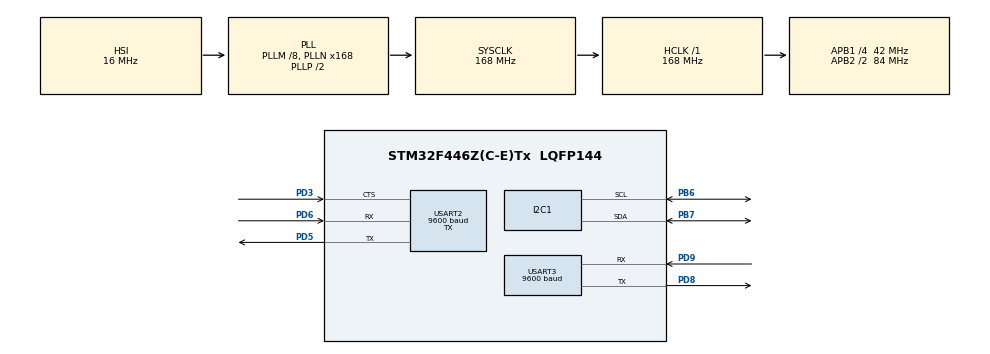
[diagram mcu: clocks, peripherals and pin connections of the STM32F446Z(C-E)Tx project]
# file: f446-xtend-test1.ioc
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Mcu.Family=STM32F4
Mcu.Name=STM32F446Z(C-E)Tx
Mcu.Package=LQFP144
NVIC.PriorityGroup=NVIC_PRIORITYGROUP_4
NVIC.TIM8_TRG_COM_TIM14_IRQn=true\:15\:0\:false\:false\:true\:false\:true
NVIC.TimeBase=TIM8_TRG_COM_TIM14_IRQn
NVIC.TimeBaseIP=TIM14
PB6.Mode=I2C
PB6.Signal=I2C1_SCL
PB7.Mode=I2C
PB7.Signal=I2C1_SDA
PC10.Signal=UART4_TX
PC11.Signal=UART4_RX
PD3.Mode=CTS_Only
PD3.Signal=USART2_CTS
PD5.Mode=Asynchronous
PD5.Signal=USART2_TX
PD6.Mode=Asynchronous
PD6.Signal=USART2_RX
PD8.Mode=Asynchronous
PD8.Signal=USART3_TX
PD9.Mode=Asynchronous
PD9.Signal=USART3_RX
ProjectManager.HeapSize=0x200
ProjectManager.StackSize=0x400
ProjectManager.TargetToolchain=STM32CubeIDE
RCC.48MHZClocksFreq_Value=24000000
RCC.AHBFreq_Value=168000000
RCC.APB1CLKDivider=RCC_HCLK_DIV4
RCC.APB1Freq_Value=42000000
RCC.APB1TimFreq_Value=84000000
RCC.APB2CLKDivider=RCC_HCLK_DIV2
RCC.APB2Freq_Value=84000000
RCC.APB2TimFreq_Value=168000000
RCC.CortexFreq_Value=168000000
RCC.HCLKFreq_Value=168000000
RCC.HSE_VALUE=8000000
RCC.HSI_VALUE=16000000
RCC.PLLM=8
RCC.PLLMUL=RCC_PLL_MUL9
RCC.PLLN=168
RCC.PLLQ=7
RCC.PRESCALERUSB=RCC_USBCLKSOURCE_PLL_DIV1_5
RCC.SYSCLKFreq_VALUE=168000000
RCC.SYSCLKSource=RCC_SYSCLKSOURCE_PLLCLK
RCC.SYSCLKSourceVirtual=RCC_SYSCLKSOURCE_PLLCLK
RCC.USBFreq_Value=48000000
RCC.VCOOutputFreq_Value=336000000
USART2.BaudRate=9600
USART2.Mode=MODE_TX
USART2.OverSampling=UART_OVERSAMPLING_8
USART2.VirtualMode=VM_ASYNC
USART3.BaudRate=9600
USART3.VirtualMode=VM_ASYNC
VP_SYS_VS_tim14.Mode=TIM14
board=NUCLEO-F446ZE

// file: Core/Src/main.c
/* USER CODE BEGIN Header */
/**
  ******************************************************************************
  * @file           : main.c
  * @brief          : Main program body
  ******************************************************************************
  * @attention
  *
  * <h2><center>&copy; Copyright (c) 2022 STMicroelectronics.
  * All rights reserved.</center></h2>
  *
  * This software component is licensed by ST under BSD 3-Clause license,
  * the "License"; You may not use this file except in compliance with the
  * License. You may obtain a copy of the License at:
  *                        opensource.org/licenses/BSD-3-Clause
  *
  ******************************************************************************
  */
/* USER CODE END Header */
#include "main.h"

/* USER CODE BEGIN Includes */
#include "stdio.h"
/* USER CODE END Includes */

I2C_HandleTypeDef hi2c1;

UART_HandleTypeDef huart2;
UART_HandleTypeDef huart3;

void SystemClock_Config(void);
static void MX_GPIO_Init(void);
static void MX_USART3_UART_Init(void);
static void MX_I2C1_Init(void);
static void MX_USART2_UART_Init(void);

/* USER CODE BEGIN PFP */
static void XTend_Transmit(char *Msg);
/* USER CODE END PFP */

int main(void)
{

  /* MCU Configuration--------------------------------------------------------*/

  /* Reset of all peripherals, Initializes the Flash interface and the Systick. */
  HAL_Init();

  /* Configure the system clock */
  SystemClock_Config();

  /* Initialize all configured peripherals */
  MX_GPIO_Init();
  MX_USART3_UART_Init(); // Serial monitor
  MX_I2C1_Init();
  MX_USART2_UART_Init(); // XTend DIn, DOut, !CTS
  /* USER CODE BEGIN 2 */

  uint8_t Start[] = "Starting XTend\r\n";
  HAL_UART_Transmit(&huart3, Start, 16, HAL_MAX_DELAY);

  XTend_Transmit("You would not believe your eyes\r\n");

  /* USER CODE END 2 */

  /* Infinite loop */
  /* USER CODE BEGIN WHILE */
  while (1)
  {

	  uint8_t Msg[] = "If ten thousand fireflies\r\n";
	  HAL_UART_Transmit(&huart2, Msg, 27, HAL_Delay);

	  HAL_Delay(30000);
    /* USER CODE END WHILE */

  }
}

void SystemClock_Config(void)
{
  RCC_OscInitTypeDef RCC_OscInitStruct = {0};
  RCC_ClkInitTypeDef RCC_ClkInitStruct = {0};

  /** Configure the main internal regulator output voltage
  */
  __HAL_RCC_PWR_CLK_ENABLE();
  __HAL_PWR_VOLTAGESCALING_CONFIG(PWR_REGULATOR_VOLTAGE_SCALE1);
  /** Initializes the RCC Oscillators according to the specified parameters
  * in the RCC_OscInitTypeDef structure.
  */
  RCC_OscInitStruct.OscillatorType = RCC_OSCILLATORTYPE_HSI;
  RCC_OscInitStruct.HSIState = RCC_HSI_ON;
  RCC_OscInitStruct.HSICalibrationValue = RCC_HSICALIBRATION_DEFAULT;
  RCC_OscInitStruct.PLL.PLLState = RCC_PLL_ON;
  RCC_OscInitStruct.PLL.PLLSource = RCC_PLLSOURCE_HSI;
  RCC_OscInitStruct.PLL.PLLM = 8;
  RCC_OscInitStruct.PLL.PLLN = 168;
  RCC_OscInitStruct.PLL.PLLP = RCC_PLLP_DIV2;
  RCC_OscInitStruct.PLL.PLLQ = 7;
  RCC_OscInitStruct.PLL.PLLR = 2;
  if (HAL_RCC_OscConfig(&RCC_OscInitStruct) != HAL_OK)
  {
    Error_Handler();
  }
  /** Initializes the CPU, AHB and APB buses clocks
  */
  RCC_ClkInitStruct.ClockType = RCC_CLOCKTYPE_HCLK|RCC_CLOCKTYPE_SYSCLK
                              |RCC_CLOCKTYPE_PCLK1|RCC_CLOCKTYPE_PCLK2;
  RCC_ClkInitStruct.SYSCLKSource = RCC_SYSCLKSOURCE_PLLCLK;
  RCC_ClkInitStruct.AHBCLKDivider = RCC_SYSCLK_DIV1;
  RCC_ClkInitStruct.APB1CLKDivider = RCC_HCLK_DIV4;
  RCC_ClkInitStruct.APB2CLKDivider = RCC_HCLK_DIV2;

  if (HAL_RCC_ClockConfig(&RCC_ClkInitStruct, FLASH_LATENCY_5) != HAL_OK)
  {
    Error_Handler();
  }
}

static void MX_I2C1_Init(void)
{

  hi2c1.Instance = I2C1;
  hi2c1.Init.ClockSpeed = 100000;
  hi2c1.Init.DutyCycle = I2C_DUTYCYCLE_2;
  hi2c1.Init.OwnAddress1 = 0;
  hi2c1.Init.AddressingMode = I2C_ADDRESSINGMODE_7BIT;
  hi2c1.Init.DualAddressMode = I2C_DUALADDRESS_DISABLE;
  hi2c1.Init.OwnAddress2 = 0;
  hi2c1.Init.GeneralCallMode = I2C_GENERALCALL_DISABLE;
  hi2c1.Init.NoStretchMode = I2C_NOSTRETCH_DISABLE;
  if (HAL_I2C_Init(&hi2c1) != HAL_OK)
  {
    Error_Handler();
  }

}

static void MX_USART2_UART_Init(void)
{

  huart2.Instance = USART2;
  huart2.Init.BaudRate = 9600;
  huart2.Init.WordLength = UART_WORDLENGTH_8B;
  huart2.Init.StopBits = UART_STOPBITS_1;
  huart2.Init.Parity = UART_PARITY_NONE;
  huart2.Init.Mode = UART_MODE_TX;
  huart2.Init.HwFlowCtl = !UART_HWCONTROL_CTS; // CTS bit is inverted
  huart2.Init.OverSampling = UART_OVERSAMPLING_8;
  if (HAL_UART_Init(&huart2) != HAL_OK)
  {
    Error_Handler();
  }

}

static void MX_USART3_UART_Init(void)
{

  huart3.Instance = USART3;
  huart3.Init.BaudRate = 9600;
  huart3.Init.WordLength = UART_WORDLENGTH_8B;
  huart3.Init.StopBits = UART_STOPBITS_1;
  huart3.Init.Parity = UART_PARITY_NONE;
  huart3.Init.Mode = UART_MODE_TX_RX;
  huart3.Init.HwFlowCtl = UART_HWCONTROL_NONE;
  huart3.Init.OverSampling = UART_OVERSAMPLING_16;
  if (HAL_UART_Init(&huart3) != HAL_OK)
  {
    Error_Handler();
  }

}

static void MX_GPIO_Init(void)
{
  GPIO_InitTypeDef GPIO_InitStruct = {0};

  /* GPIO Ports Clock Enable */
  __HAL_RCC_GPIOD_CLK_ENABLE();
  __HAL_RCC_GPIOC_CLK_ENABLE();
  __HAL_RCC_GPIOB_CLK_ENABLE();

  /*Configure GPIO pins : PC10 PC11 */
  GPIO_InitStruct.Pin = GPIO_PIN_10|GPIO_PIN_11;
  GPIO_InitStruct.Mode = GPIO_MODE_AF_PP;
  GPIO_InitStruct.Pull = GPIO_NOPULL;
  GPIO_InitStruct.Speed = GPIO_SPEED_FREQ_VERY_HIGH;
  GPIO_InitStruct.Alternate = GPIO_AF8_UART4;
  HAL_GPIO_Init(GPIOC, &GPIO_InitStruct);

}

/* USER CODE BEGIN 4 */
/**
 * @brief   Function to transmit message to XTend
 * @param  Msg : char array (range 1-800)
 */
static void XTend_Transmit(char *Msg){
	HAL_UART_Transmit(&huart2, Msg, strlen(Msg), HAL_Delay);
}

/* USER CODE END 4 */

void HAL_TIM_PeriodElapsedCallback(TIM_HandleTypeDef *htim)
{
  if (htim->Instance == TIM14) {
    HAL_IncTick();
  }
}

void Error_Handler(void)
{
  __disable_irq();
  while (1)
  {
  }
}

/************************ (C) COPYRIGHT STMicroelectronics *****END OF FILE****/
